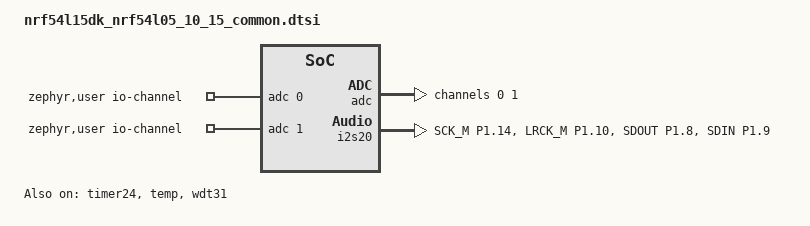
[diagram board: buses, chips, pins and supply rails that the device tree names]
/*
 * Copyright (c) 2025 Nordic Semiconductor ASA
 *
 * SPDX-License-Identifier: LicenseRef-Nordic-5-Clause
 */

/ {
	aliases {
		i2s-node0 = &i2s20;
		test-counter = &timer24;
	};

	zephyr,user {
		io-channels = <&adc 0>, <&adc 1>;
	};
};

&pinctrl {
	i2s20_default_alt: i2s20_default_alt {
		group1 {
			psels = <NRF_PSEL(I2S_SCK_M, 1, 14)>,
				<NRF_PSEL(I2S_LRCK_M, 1, 10)>,
				<NRF_PSEL(I2S_SDOUT, 1, 8)>,
				<NRF_PSEL(I2S_SDIN, 1, 9)>;
		};
	};
};

&adc {
	#address-cells = <1>;
	#size-cells = <0>;

	channel@0 {
		reg = <0>;
		zephyr,gain = "ADC_GAIN_1";
		zephyr,reference = "ADC_REF_INTERNAL";
		zephyr,acquisition-time = <ADC_ACQ_TIME(ADC_ACQ_TIME_MICROSECONDS, 10)>;
		zephyr,input-positive = <NRF_SAADC_AIN4>; /* P1.11 - I2C SCL on sensor shield */
		zephyr,resolution = <10>;
	};

	channel@1 {
		reg = <1>;
		zephyr,gain = "ADC_GAIN_1_4";
		zephyr,reference = "ADC_REF_INTERNAL";
		zephyr,acquisition-time = <ADC_ACQ_TIME_DEFAULT>;
		zephyr,input-positive = <NRF_SAADC_AIN5>; /* P1.12 - I2C SDA on sensor shield */
		zephyr,resolution = <12>;
	};
};

&i2s20 {
	status = "okay";
	pinctrl-0 = <&i2s20_default_alt>;
	pinctrl-names = "default";
};

&timer24 {
	status = "okay";
	prescaler = <4>;
};

temp_sensor: &temp {
	status = "okay";
};

&wdt31 {
	status = "okay";
};
